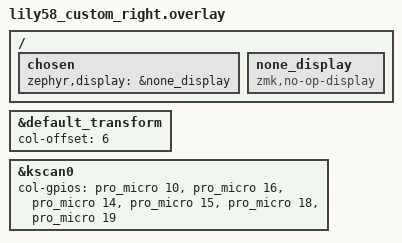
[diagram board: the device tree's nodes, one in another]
/*
 * Copyright (c) 2020 Pete Johanson
 *
 * SPDX-License-Identifier: MIT
 */

#include "lily58.dtsi"

/ {
    chosen {
        zephyr,display = &none_display;
    };

    none_display: none_display {
        compatible = "zmk,no-op-display";
        status = "okay";
    };
};

&default_transform {
    col-offset = <6>;
};

&kscan0 {
    col-gpios
        = <&pro_micro 10 GPIO_ACTIVE_HIGH>
        , <&pro_micro 16 GPIO_ACTIVE_HIGH>
        , <&pro_micro 14 GPIO_ACTIVE_HIGH>
        , <&pro_micro 15 GPIO_ACTIVE_HIGH>
        , <&pro_micro 18 GPIO_ACTIVE_HIGH>
        , <&pro_micro 19 GPIO_ACTIVE_HIGH>
        ;
};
